VERSION ""

NS_ :

BS_:

BU_:

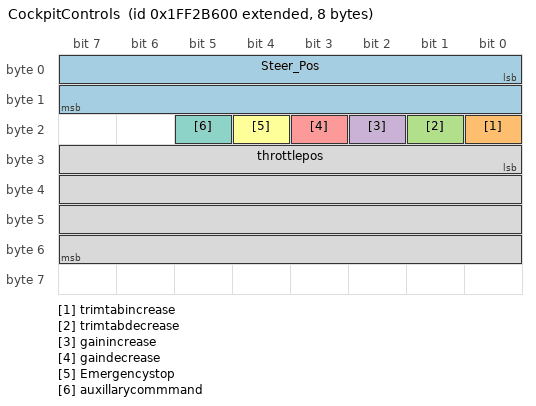
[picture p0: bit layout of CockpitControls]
BO_ 2683483648 CockpitControls: 8 Vector__XXX
 SG_ Steer_Pos : 0|16@1- (1,0) [0|0] "" Vector__XXX
 SG_ trimtabincrease : 16|1@1+ (1,0) [0|1] "" Vector__XXX
 SG_ trimtabdecrease : 17|1@1+ (1,0) [0|1] "" Vector__XXX
 SG_ gainincrease : 18|1@1+ (1,0) [0|1] "" Vector__XXX
 SG_ gaindecrease : 19|1@1+ (1,0) [0|1] "" Vector__XXX
 SG_ Emergencystop : 20|1@1+ (1,0) [0|1] "" Vector__XXX
 SG_ auxillarycommmand : 21|1@1+ (1,0) [0|1] "" Vector__XXX
 SG_ throttlepos : 24|32@1- (1,0) [0|30] "" Vector__XXX

SIG_VALTYPE_ 2683483648 throttlepos : 1;
